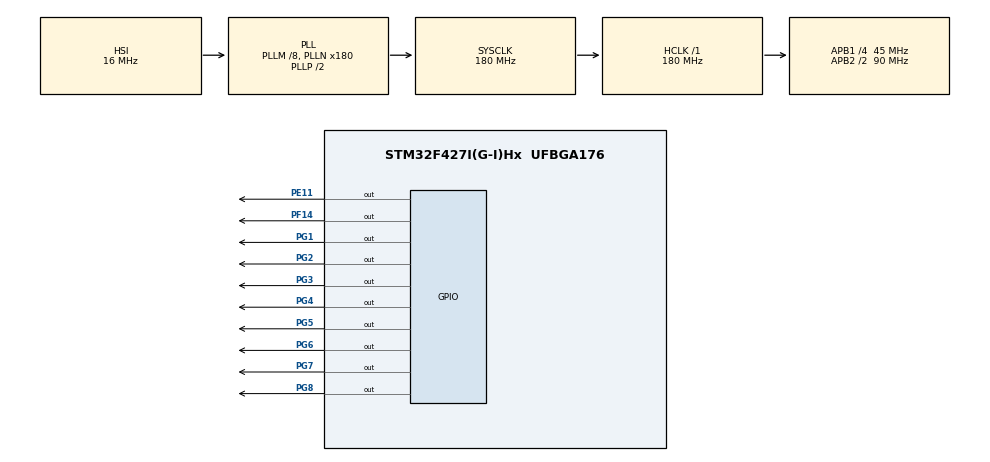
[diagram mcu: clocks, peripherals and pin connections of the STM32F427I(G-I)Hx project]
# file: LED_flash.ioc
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Mcu.Family=STM32F4
Mcu.Name=STM32F427I(G-I)Hx
Mcu.Package=UFBGA176
NVIC.PriorityGroup=NVIC_PRIORITYGROUP_4
PE11.Signal=GPIO_Output
PF14.Signal=GPIO_Output
PG1.Signal=GPIO_Output
PG2.Signal=GPIO_Output
PG3.Signal=GPIO_Output
PG4.Signal=GPIO_Output
PG5.Signal=GPIO_Output
PG6.Signal=GPIO_Output
PG7.Signal=GPIO_Output
PG8.Signal=GPIO_Output
ProjectManager.HeapSize=0x200
ProjectManager.StackSize=0x400
ProjectManager.TargetToolchain=STM32CubeIDE
RCC.48MHZClocksFreq_Value=90000000
RCC.AHBFreq_Value=180000000
RCC.APB1CLKDivider=RCC_HCLK_DIV4
RCC.APB1Freq_Value=45000000
RCC.APB1TimFreq_Value=90000000
RCC.APB2CLKDivider=RCC_HCLK_DIV2
RCC.APB2Freq_Value=90000000
RCC.APB2TimFreq_Value=180000000
RCC.CortexFreq_Value=180000000
RCC.HCLKFreq_Value=180000000
RCC.HSE_VALUE=25000000
RCC.HSI_VALUE=16000000
RCC.LSE_VALUE=32768
RCC.PLLM=8
RCC.PLLN=180
RCC.SYSCLKFreq_VALUE=180000000
RCC.SYSCLKSource=RCC_SYSCLKSOURCE_PLLCLK
RCC.VCOOutputFreq_Value=360000000
board=custom

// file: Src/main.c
/* USER CODE BEGIN Header */
/**
  ******************************************************************************
  * @file           : main.c
  * @brief          : Main program body
  ******************************************************************************
  * @attention
  *
  * <h2><center>&copy; Copyright (c) 2019 STMicroelectronics.
  * All rights reserved.</center></h2>
  *
  * This software component is licensed by ST under BSD 3-Clause license,
  * the "License"; You may not use this file except in compliance with the
  * License. You may obtain a copy of the License at:
  *                        opensource.org/licenses/BSD-3-Clause
  *
  ******************************************************************************
  */
/* USER CODE END Header */

#include "main.h"

void SystemClock_Config(void);
static void MX_GPIO_Init(void);

int main(void)
{

  /* MCU Configuration--------------------------------------------------------*/

  /* Reset of all peripherals, Initializes the Flash interface and the Systick. */
  HAL_Init();

  /* Configure the system clock */
  SystemClock_Config();

  /* Initialize all configured peripherals */
  MX_GPIO_Init();

  /* Infinite loop */
  while (1)
  {

    /* USER CODE BEGIN 3 */
	  HAL_Delay(500);
	  HAL_GPIO_TogglePin(GPIOG, GPIO_PIN_1);
	  HAL_GPIO_TogglePin(GPIOE, GPIO_PIN_11);
	  HAL_GPIO_TogglePin(GPIOF, GPIO_PIN_14);
  }
  /* USER CODE END 3 */
}

void SystemClock_Config(void)
{
  RCC_OscInitTypeDef RCC_OscInitStruct = {0};
  RCC_ClkInitTypeDef RCC_ClkInitStruct = {0};

  /** Configure the main internal regulator output voltage
  */
  __HAL_RCC_PWR_CLK_ENABLE();
  __HAL_PWR_VOLTAGESCALING_CONFIG(PWR_REGULATOR_VOLTAGE_SCALE1);
  /** Initializes the CPU, AHB and APB busses clocks
  */
  RCC_OscInitStruct.OscillatorType = RCC_OSCILLATORTYPE_HSI;
  RCC_OscInitStruct.HSIState = RCC_HSI_ON;
  RCC_OscInitStruct.HSICalibrationValue = RCC_HSICALIBRATION_DEFAULT;
  RCC_OscInitStruct.PLL.PLLState = RCC_PLL_ON;
  RCC_OscInitStruct.PLL.PLLSource = RCC_PLLSOURCE_HSI;
  RCC_OscInitStruct.PLL.PLLM = 8;
  RCC_OscInitStruct.PLL.PLLN = 180;
  RCC_OscInitStruct.PLL.PLLP = RCC_PLLP_DIV2;
  RCC_OscInitStruct.PLL.PLLQ = 4;
  if (HAL_RCC_OscConfig(&RCC_OscInitStruct) != HAL_OK)
  {
    Error_Handler();
  }
  /** Activate the Over-Drive mode
  */
  if (HAL_PWREx_EnableOverDrive() != HAL_OK)
  {
    Error_Handler();
  }
  /** Initializes the CPU, AHB and APB busses clocks
  */
  RCC_ClkInitStruct.ClockType = RCC_CLOCKTYPE_HCLK|RCC_CLOCKTYPE_SYSCLK
                              |RCC_CLOCKTYPE_PCLK1|RCC_CLOCKTYPE_PCLK2;
  RCC_ClkInitStruct.SYSCLKSource = RCC_SYSCLKSOURCE_PLLCLK;
  RCC_ClkInitStruct.AHBCLKDivider = RCC_SYSCLK_DIV1;
  RCC_ClkInitStruct.APB1CLKDivider = RCC_HCLK_DIV4;
  RCC_ClkInitStruct.APB2CLKDivider = RCC_HCLK_DIV2;

  if (HAL_RCC_ClockConfig(&RCC_ClkInitStruct, FLASH_LATENCY_5) != HAL_OK)
  {
    Error_Handler();
  }
}

static void MX_GPIO_Init(void)
{
  GPIO_InitTypeDef GPIO_InitStruct = {0};

  /* GPIO Ports Clock Enable */
  __HAL_RCC_GPIOG_CLK_ENABLE();
  __HAL_RCC_GPIOE_CLK_ENABLE();
  __HAL_RCC_GPIOF_CLK_ENABLE();

  /*Configure GPIO pin Output Level */
  HAL_GPIO_WritePin(GPIOG, GPIO_PIN_8|GPIO_PIN_7|GPIO_PIN_6|GPIO_PIN_5
                          |GPIO_PIN_4|GPIO_PIN_3|GPIO_PIN_2|GPIO_PIN_1, GPIO_PIN_RESET);

  /*Configure GPIO pin Output Level */
  HAL_GPIO_WritePin(GPIOE, GPIO_PIN_11, GPIO_PIN_RESET);

  /*Configure GPIO pin Output Level */
  HAL_GPIO_WritePin(GPIOF, GPIO_PIN_14, GPIO_PIN_RESET);

  /*Configure GPIO pins : PG8 PG7 PG6 PG5
                           PG4 PG3 PG2 PG1 */
  GPIO_InitStruct.Pin = GPIO_PIN_8|GPIO_PIN_7|GPIO_PIN_6|GPIO_PIN_5
                          |GPIO_PIN_4|GPIO_PIN_3|GPIO_PIN_2|GPIO_PIN_1;
  GPIO_InitStruct.Mode = GPIO_MODE_OUTPUT_PP;
  GPIO_InitStruct.Pull = GPIO_NOPULL;
  GPIO_InitStruct.Speed = GPIO_SPEED_FREQ_LOW;
  HAL_GPIO_Init(GPIOG, &GPIO_InitStruct);

  /*Configure GPIO pin : PE11 */
  GPIO_InitStruct.Pin = GPIO_PIN_11;
  GPIO_InitStruct.Mode = GPIO_MODE_OUTPUT_PP;
  GPIO_InitStruct.Pull = GPIO_NOPULL;
  GPIO_InitStruct.Speed = GPIO_SPEED_FREQ_LOW;
  HAL_GPIO_Init(GPIOE, &GPIO_InitStruct);

  /*Configure GPIO pin : PF14 */
  GPIO_InitStruct.Pin = GPIO_PIN_14;
  GPIO_InitStruct.Mode = GPIO_MODE_OUTPUT_PP;
  GPIO_InitStruct.Pull = GPIO_NOPULL;
  GPIO_InitStruct.Speed = GPIO_SPEED_FREQ_LOW;
  HAL_GPIO_Init(GPIOF, &GPIO_InitStruct);

}

void Error_Handler(void)
{
}

/************************ (C) COPYRIGHT STMicroelectronics *****END OF FILE****/
